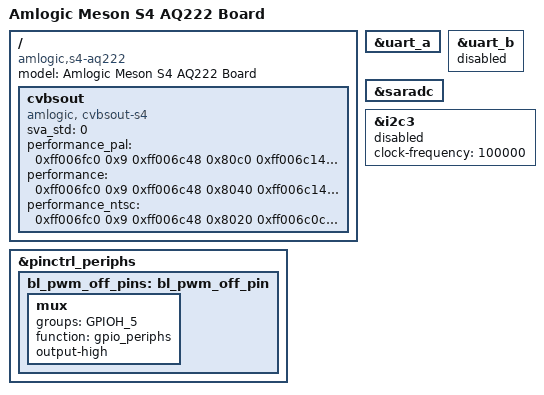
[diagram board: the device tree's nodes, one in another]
/*
 * Copyright (c) 2016 Endless Computers, Inc.
 * Author: Carlo Caione <carlo@endlessm.com>
 *
 * This file is dual-licensed: you can use it either under the terms
 * of the GPL or the X11 license, at your option. Note that this dual
 * licensing only applies to this file, and not this project as a
 * whole.
 *
 *  a) This library is free software; you can redistribute it and/or
 *     modify it under the terms of the GNU General Public License as
 *     published by the Free Software Foundation; either version 2 of the
 *     License, or (at your option) any later version.
 *
 *     This library is distributed in the hope that it will be useful,
 *     but WITHOUT ANY WARRANTY; without even the implied warranty of
 *     MERCHANTABILITY or FITNESS FOR A PARTICULAR PURPOSE.  See the
 *     GNU General Public License for more details.
 *
 * Or, alternatively,
 *
 *  b) Permission is hereby granted, free of charge, to any person
 *     obtaining a copy of this software and associated documentation
 *     files (the "Software"), to deal in the Software without
 *     restriction, including without limitation the rights to use,
 *     copy, modify, merge, publish, distribute, sublicense, and/or
 *     sell copies of the Software, and to permit persons to whom the
 *     Software is furnished to do so, subject to the following
 *     conditions:
 *
 *     The above copyright notice and this permission notice shall be
 *     included in all copies or substantial portions of the Software.
 *
 *     THE SOFTWARE IS PROVIDED "AS IS", WITHOUT WARRANTY OF ANY KIND,
 *     EXPRESS OR IMPLIED, INCLUDING BUT NOT LIMITED TO THE WARRANTIES
 *     OF MERCHANTABILITY, FITNESS FOR A PARTICULAR PURPOSE AND
 *     NONINFRINGEMENT. IN NO EVENT SHALL THE AUTHORS OR COPYRIGHT
 *     HOLDERS BE LIABLE FOR ANY CLAIM, DAMAGES OR OTHER LIABILITY,
 *     WHETHER IN AN ACTION OF CONTRACT, TORT OR OTHERWISE, ARISING
 *     FROM, OUT OF OR IN CONNECTION WITH THE SOFTWARE OR THE USE OR
 *     OTHER DEALINGS IN THE SOFTWARE.
 */

/dts-v1/;

#include "meson-s4-aq222.dtsi"
#include "meson-s4_skt-panel.dtsi"

/ {
	compatible = "amlogic,s4-aq222", "amlogic,s4-txxx", "amlogic,meson-s4";
	model = "Amlogic Meson S4 AQ222 Board";

	cvbsout {
		compatible = "amlogic, cvbsout-s4";
		status = "okay";
		sva_std = <0>; /* if default sva test this value is 1*/

		/* performance: reg_address, reg_value */
		/* s4 */
		/* pal default Matrx625 CTCC value */
		performance_pal = <0xff006fc0  0x9 /* 0x1bf0 << 2 + 0xff000000 */
			0xff006c48  0x80c0 /* 0x1b12 */
			0xff006c14  0xf7 /* 0x1b05 */
			0xff006d58  0x333 /* 0x1b56 */
			0xff007164  0xf25c /* 0x1c59 */
			0xffff  0x0>; /* ending flag */
		/* ccitt033 SVA value */
		performance = <0xff006fc0  0x9 /* 0x1bf0 */
			0xff006c48  0x8040 /* 0x1b12 */
			0xff006c14  0xfd /* 0x1b05 */
			0xff006d58  0x333 /* 0x1b56 */
			0xff007164  0xf654 /* 0x1c59 */
			0xffff  0x0>; /* ending flag */
		performance_ntsc = <0xff006fc0  0x9 /* 0x1bf0 << 2 + 0xff000000 */
			0xff006c48  0x8020 /* 0x1b12 */
                        0xff006c0c  0x0 /* 0x1b03 */
                        0xff006c10  0x0 /* 0x1b04 */
			0xff006c14  0x0 /* 0x1b05 */
			0xff006d58  0x333 /* 0x1b56 */
			0xff007164  0xf850 /* 0x1c59 */
			0xffff  0x0>; /* ending flag */
	};
};

/* This UART is brought out to the DB9 connector */
&uart_a {
	status = "okay";
};

&uart_b {
	status = "disabled";
};

&saradc {
	status = "okay";
};

/* demo for i2c user */
&i2c3 {
	status= "disabled";
	clock-frequency = <100000>;
	/* pinctrl-names = "default";*/
	/* pinctrl-0 = <&i2c3_master_pins2>;*/
};

&pinctrl_periphs {
	bl_pwm_off_pins:bl_pwm_off_pin {
		mux {
			groups = "GPIOH_5";
			function = "gpio_periphs";
			output-high;
		};
	};
}; /* end of pinctrl_periphs */
